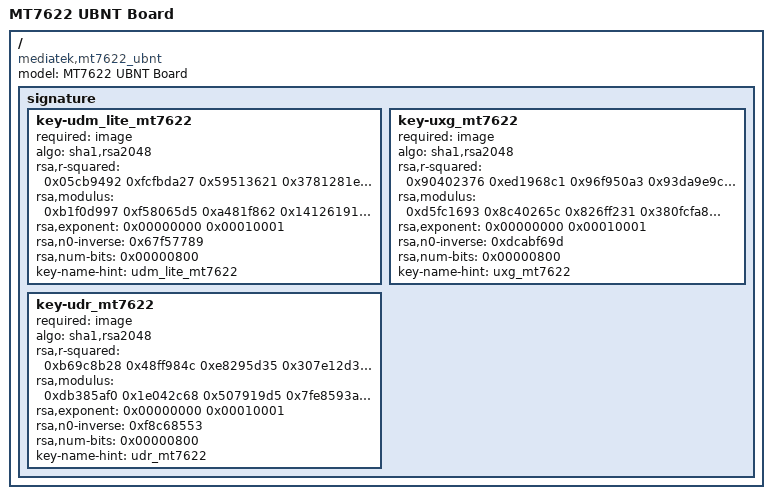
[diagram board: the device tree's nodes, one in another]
/dts-v1/;
#include "mt7622.dtsi"

/ {
	model = "MT7622 UBNT Board";
	compatible = "mediatek,mt7622_ubnt";
	signature {
		key-udm_lite_mt7622 {
				required = "image";
				algo = "sha1,rsa2048";
				rsa,r-squared = <0x05cb9492 0xfcfbda27 0x59513621 0x3781281e 0xd308dcd4 0x8609ae74 0xc2da5cb5 0xed1dbdf6 0xd5463d0b 0xdb66da50 0xe866df42 0x73cc5c6d 0x71e39fa5 0xbd505376 0x5a2c57b9 0x609100a0 0xff50833b 0x144a2ef4 0xa8e338dd 0xb971f6c1 0x8f6505b2 0x50eeff4a 0x7413340a 0x3c90c421 0x09672667 0x78b400d7 0xbbca71cb 0x780f044e 0x75163421 0x7ef87a33 0xefcbba5c 0xe071430a 0x38366f8e 0x8a72399f 0x36e61d64 0x42651e98 0x39c34bfc 0xc8249017 0x173fefab 0xcae28188 0xc7842277 0x48fb06be 0x9b21e590 0x4852cbbc 0x511341bc 0x7dd59351 0x32a3a9b7 0xeb6ab563 0x169cb075 0xdda9f549 0x77662fa7 0xfa223133 0x99b1bcba 0x57793f62 0x0d00a5bd 0x6bc68b04 0xa2226387 0xd6dc14f8 0xdff1315b 0x7d7b0671 0x3c51cc63 0xe66d1299 0x39e1ce8f 0xa712aa13>;
				rsa,modulus = <0xb1f0d997 0xf58065d5 0xa481f862 0x14126191 0xf57a0da0 0xc308e661 0xb17447bb 0x12281854 0xd3f8131d 0x543ab3b3 0x3d7e7db9 0xba7b208c 0x7168393a 0x0fdc5f28 0x40daaef2 0xd9a2e46b 0x158d4209 0x08b35171 0xc2e3f823 0x79ba0ee7 0x8420b4ee 0xb0899285 0x0aabd373 0xa9e5c6c5 0xf5a9c077 0xf7461b06 0xff21824e 0xc1fb996c 0x3acabf73 0x920ed072 0x6d657274 0xbad2f212 0x5c7f1ab4 0x1fb1740c 0x2496df83 0x9d741c3e 0x867e3242 0xf64e50bd 0xb5baf843 0x2ae24abd 0x34418a19 0x169ed27c 0x1d435367 0x9541b53b 0xad44ffc7 0x9a6a349e 0x46be8dff 0xcabfe731 0x19d5d245 0x88073fdc 0x20e7a0d9 0x212dd447 0x2ae829ca 0xc4e27411 0x975bf7f6 0x5c02589d 0x3f1daac0 0x72ee6f71 0x3cd37792 0xda52d0d4 0x6393c8c7 0xcfd9c67b 0xa4b381d5 0x276dd147>;
				rsa,exponent = <0x00000000 0x00010001>;
				rsa,n0-inverse = <0x67f57789>;
				rsa,num-bits = <0x00000800>;
				key-name-hint = "udm_lite_mt7622";
		};
		key-uxg_mt7622 {
				required = "image";
				algo = "sha1,rsa2048";
				rsa,r-squared = <0x90402376 0xed1968c1 0x96f950a3 0x93da9e9c 0xe1523e1b 0xaa942e99 0x29516b76 0xb7ae7a31 0xd3c8f1ec 0xb9e5d51c 0x74819b4e 0x90492689 0x5fb3aae9 0xd74f722b 0x4efa348f 0x95ac68fb 0xaa9c9e71 0x8a0dd843 0x41cdf46d 0xa68031dc 0x2ac3fdbb 0xde77e4cc 0x93305c6d 0x6e0f016d 0xaaaf5673 0xedb2c20a 0x804dc099 0x96fcfea1 0x0f62c92a 0x1493f1ef 0xa35be312 0x5070e891 0x02ae8595 0x6915e27d 0x2c16cbd4 0x4ca2191e 0x7409ad00 0x6f8c0ca7 0x1919ca72 0xaf66d64c 0x89e962d1 0x8bd5130d 0x014ce25e 0xb139576a 0xfab71ea0 0x420f4d4e 0x6ecb48c8 0x1aa1c441 0xd2865179 0x6ac8db2a 0x6176f4c8 0x208dc919 0x1129e964 0x9f98f8ab 0xeb8eccfd 0x7d4aa97d 0xbf2a36b7 0x3e963ed1 0x9872371b 0xa9139520 0x7681094c 0x470d33b4 0xeb0a2783 0xf8e7e9b7>;
				rsa,modulus = <0xd5fc1693 0x8c40265c 0x826ff231 0x380fcfa8 0x474b7214 0xeb23721b 0xf95928cc 0xb530a56f 0x84943a15 0x63f58ff3 0xddc0690e 0xed72a1f2 0xc20c474b 0xf8723628 0x1421dbb2 0xd477f70e 0xfa1da663 0x06913cde 0x089fc23a 0x29ace497 0x534b5641 0x64c5e5ae 0x3f2e9dea 0xd5480206 0x4a598fe2 0x22ece2ab 0x9f717ce4 0xf660f23f 0x3c007fb1 0x8498a432 0xc7a5912d 0x3312ed8a 0xb0b764a5 0x739a963e 0x426eaafe 0x7d1bb708 0x8f65fc9a 0xd676b68d 0x98907179 0x93031d52 0x1630e79b 0x3f170587 0x4df62b77 0x3217e08e 0x0848ebf9 0x45ea9735 0xe3f5f099 0xd2fb4930 0xc42be03e 0x7d9ee3f6 0xa42f3d09 0xf971121c 0x47e3671f 0xf05a4394 0xea369ba0 0x03f87f8c 0xe4ed070e 0x77a814f5 0x342d5db6 0xdbf715d5 0xb6a360eb 0x125af866 0x74783aa8 0xee7dc04b>;
				rsa,exponent = <0x00000000 0x00010001>;
				rsa,n0-inverse = <0xdcabf69d>;
				rsa,num-bits = <0x00000800>;
				key-name-hint = "uxg_mt7622";
		};
		key-udr_mt7622 {
				required = "image";
				algo = "sha1,rsa2048";
				rsa,r-squared = <0xb69c8b28 0x48ff984c 0xe8295d35 0x307e12d3 0xa224068f 0xba0d9af3 0x8b267042 0xaa5e66f0 0x72005ae9 0xb8d62638 0x3f28c4fe 0xf4a1caed 0x9e376290 0x25976a97 0x41c933a1 0x40d2d243 0x6a98ac07 0x3251a100 0x86c06ace 0xcb7214ef 0x977879b9 0xcb364382 0xbfe56827 0xedafaf6c 0x3c53de85 0xfbc18d6b 0x4bff3d0d 0x2b36f09f 0x61e193fc 0xe2eec33d 0x5b098626 0xf4bb8344 0x3bc8143f 0x3edbc70c 0xcf95da34 0x5ea763b6 0x8b0cb9df 0x736fb79e 0xaf7cccdf 0x39de52d6 0x991e7a3f 0xa0e98e06 0x87e950b5 0x400c4a0e 0xce7a897b 0xc74fcea0 0x29e24698 0x34525472 0xc422d860 0xd4b3e888 0xb0a7e637 0x664b8b74 0x808a9b29 0x35e7b184 0x234b121e 0xb012261f 0x400b557c 0x18fa170c 0x9ccdf147 0xba0d9dd1 0x9bdb9d44 0x9bfeecdb 0xf97e2dc1 0x640ed168>;
				rsa,modulus = <0xdb385af0 0x1e042c68 0x507919d5 0x7fe8593a 0x2fa8f832 0xf92d8858 0xad231820 0x0593985d 0x54aecdf1 0xf8b38011 0x35d12f58 0x6c5888be 0x9e21b4c5 0x7052ff9b 0x48fd2ea0 0x96d2eb20 0x4831cc6e 0x44130b7d 0x97b5b651 0x23cf6da6 0x24baa367 0x2dc30e7c 0xd71e7748 0xbb8bae74 0xffdda0f4 0xe71a8119 0x75680532 0xa6b9bfa3 0xaf788f0c 0x1be19eae 0xe69b78b5 0xc37341d9 0x0965ffbf 0x9e701912 0x253c5a99 0xe22fae3b 0x1ab25d78 0xcf7d6887 0x92ff7e5b 0x30e550ba 0x456a8982 0x05577f7b 0xcd26951a 0xb82a03fc 0x63d5758d 0x15676440 0x24da876d 0x0853ee34 0x82771907 0x7afdf5f0 0xbce984b5 0xb2b6b297 0xea4cb870 0x38a01169 0x01dbc793 0x2a274b91 0xbd826b98 0xf5ed50c2 0x5408f7a5 0x06d1608b 0xb30b4c67 0xe2a2b4ee 0x07ac4267 0x30bbf925>;
				rsa,exponent = <0x00000000 0x00010001>;
				rsa,n0-inverse = <0xf8c68553>;
				rsa,num-bits = <0x00000800>;
				key-name-hint = "udr_mt7622";
		};
	};
};
